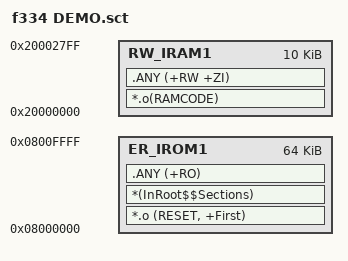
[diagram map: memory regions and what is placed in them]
; *************************************************************
; *** Scatter-Loading Description File generated by uVision ***
; *************************************************************

LR_IROM1 0x08000000 0x00010000  {    ; load region size_region
  
  ER_IROM1 0x08000000 0x00010000  {  ; load address = execution address
   *.o (RESET, +First)
   *(InRoot$$Sections)
   .ANY (+RO)
  }
  RW_IRAM1 0x20000000 0x00002800  {  ; RW data
   *.o(RAMCODE)
   .ANY (+RW +ZI)
  }
  
;  RW_IRAM2 0x10000000 0x00001000  {  ; RW data
;   *.o(RAM2CODE)
;   .ANY (+RW +ZI)
;  }
}
